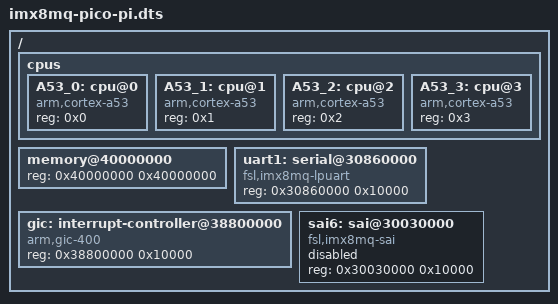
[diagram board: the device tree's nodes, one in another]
/dts-v1/;

/* A very **useful** skeleton for exercise 1 - devicetree warm-up */

/ {
		#address-cells = <1>;
		#size-cells = <1>;
	cpus {
		#address-cells = <1>;
		#size-cells = <0>;

		A53_0: cpu@0 {
			device_type = "cpu";
			compatible = "arm,cortex-a53";
			reg = <0x0>;
		};

		A53_1: cpu@1 {
			device_type = "cpu";
			compatible = "arm,cortex-a53";
			reg = <0x1>;
		};

		A53_2: cpu@2 {
			device_type = "cpu";
			compatible = "arm,cortex-a53";
			reg = <0x2>;
		};

		A53_3: cpu@3 {
			device_type = "cpu";
			compatible = "arm,cortex-a53";
			reg = <0x3>;
		};
	};

	memory@40000000 {
		device_type = "memory";
		reg = <0x40000000 0x40000000>;
	};

	uart1: serial@30860000 {
		compatible = "fsl,imx8mq-lpuart",
		             "fsl,imx8-lpuart";
		reg = <0x30860000 0x10000>;
	};

	gic: interrupt-controller@38800000 {
		compatible = "arm,gic-400";
		reg = <0x38800000 0x10000>;
	};

	sai6: sai@30030000 {
		compatible = "fsl,imx8mq-sai",
		             "fsl,imx6-sai";
		reg = <0x30030000 0x10000>;
		status = "disabled";
	};
};
